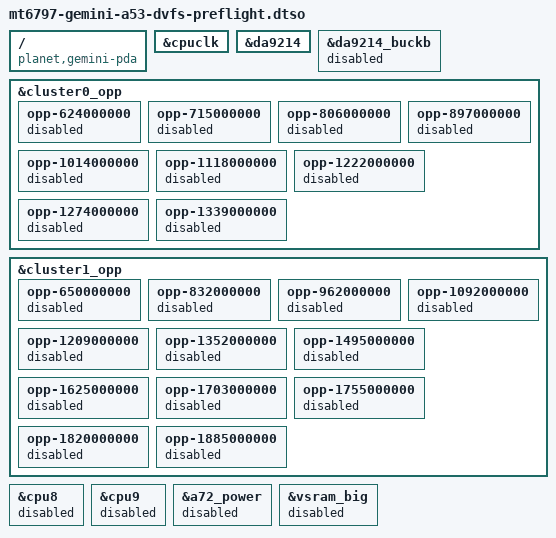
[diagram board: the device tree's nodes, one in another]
// SPDX-License-Identifier: (GPL-2.0-only OR MIT)
/*
 * Planet Computers Gemini PDA A53 DVFS preflight.
 *
 * This overlay is intended only for a volatile FIT boot.  It enables the
 * MT6797 CPU clock owner and the already-described shared A53 Vproc
 * provider, but leaves one enabled OPP per cluster.  The cpufreq driver can
 * therefore validate the live boot clocks, seed both shared-rail votes, and
 * register both policies without requesting a frequency transition.
 *
 * A72 power, CPU8/9, the secure SRAM regulator, BUCKB, divider-dependent
 * OPPs, and rates above the observed boot ceiling remain unavailable.  A
 * reset to the base FIT removes this entire candidate.
 */

/dts-v1/;
/plugin/;

/ {
	compatible = "planet,gemini-pda", "mediatek,mt6797";
};

&cpuclk {
	status = "okay";
};

&da9214 {
	status = "okay";
};

&da9214_buckb {
	status = "disabled";
};

&cluster0_opp {
	opp-624000000 {
		status = "disabled";
	};

	opp-715000000 {
		status = "disabled";
	};

	opp-806000000 {
		status = "disabled";
	};

	opp-897000000 {
		status = "disabled";
	};

	opp-1014000000 {
		status = "disabled";
	};

	opp-1118000000 {
		status = "disabled";
	};

	opp-1222000000 {
		status = "disabled";
	};

	opp-1274000000 {
		status = "disabled";
	};

	opp-1339000000 {
		status = "disabled";
	};
};

&cluster1_opp {
	opp-650000000 {
		status = "disabled";
	};

	opp-832000000 {
		status = "disabled";
	};

	opp-962000000 {
		status = "disabled";
	};

	opp-1092000000 {
		status = "disabled";
	};

	opp-1209000000 {
		status = "disabled";
	};

	opp-1352000000 {
		status = "disabled";
	};

	opp-1495000000 {
		status = "disabled";
	};

	opp-1625000000 {
		status = "disabled";
	};

	opp-1703000000 {
		status = "disabled";
	};

	opp-1755000000 {
		status = "disabled";
	};

	opp-1820000000 {
		status = "disabled";
	};

	opp-1885000000 {
		status = "disabled";
	};
};

&cpu8 {
	status = "disabled";
};

&cpu9 {
	status = "disabled";
};

&a72_power {
	status = "disabled";
};

&vsram_big {
	status = "disabled";
};
